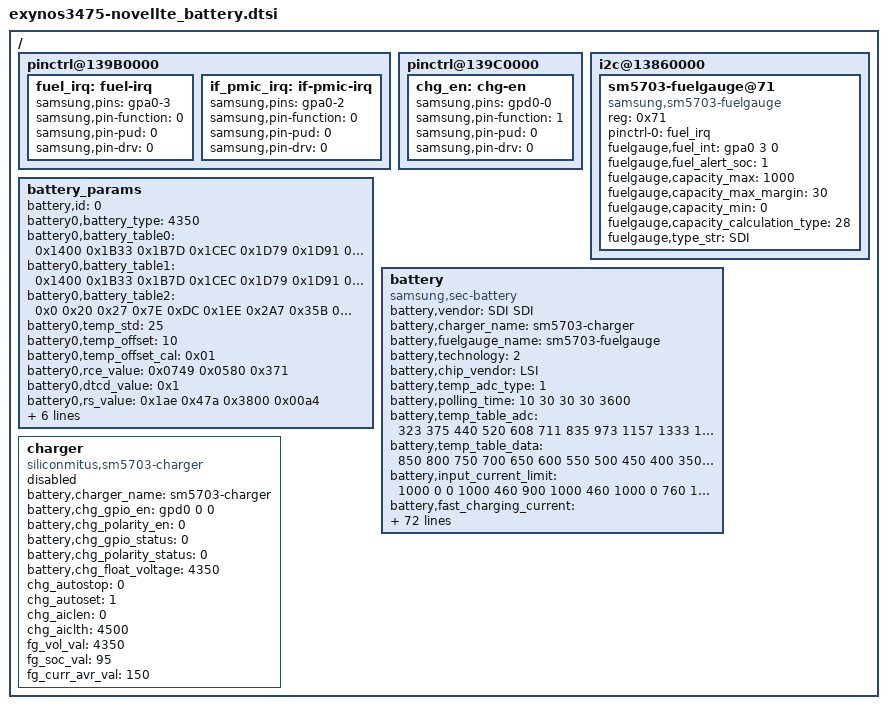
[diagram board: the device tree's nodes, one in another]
/*
 * SAMSUNG UNIVERSAL5430 board device tree source
 *
 * Copyright (c) 2013 Samsung Electronics Co., Ltd.
 *		http://www.samsung.com
 *
 * This program is free software; you can redistribute it and/or modify
 * it under the terms of the GNU General Public License version 2 as
 * published by the Free Software Foundation.
*/

/ {
	pinctrl@139B0000 {
		fuel_irq: fuel-irq {
			samsung,pins = "gpa0-3";
			samsung,pin-function = <0>;
			samsung,pin-pud = <0>;
			samsung,pin-drv = <0>;
		};
	};

	pinctrl@139B0000 {
		if_pmic_irq: if-pmic-irq {
			samsung,pins = "gpa0-2";
			samsung,pin-function = <0>;
			samsung,pin-pud = <0>;
			samsung,pin-drv = <0>;
		};
	};

	pinctrl@139C0000 {
		chg_en: chg-en {
			samsung,pins = "gpd0-0";
			samsung,pin-function = <1>;
			samsung,pin-pud = <0>;
			samsung,pin-drv = <0>;
		};
	};

	i2c@13860000 {
		status = "okay";
		sm5703-fuelgauge@71 {
			compatible = "samsung,sm5703-fuelgauge";
			reg = <0x71>;
			pinctrl-names = "default";
			pinctrl-0 = <&fuel_irq>;
			fuelgauge,fuel_int = <&gpa0 3 0>;
			fuelgauge,fuel_alert_soc = <1>;
			fuelgauge,capacity_max = <1000>;
			fuelgauge,capacity_max_margin = <30>;
			fuelgauge,capacity_min = <0>;
			fuelgauge,capacity_calculation_type = <28>;
			fuelgauge,type_str = "SDI";
		};
	};

	battery_params {
		battery,id = <0>;
		battery0,battery_type = <4350>; /* 4200 4350 4400 */
		battery0,battery_table0 = <0x1400 0x1B33 0x1B7D 0x1CEC 0x1D79 0x1D91 0x1DE9 0x1E19 0x1EA3 0x1EDD 0x1F4E 0x1FD2 0x2086 0x20A5 0x226F 0x2399>;
		battery0,battery_table1 = <0x1400 0x1B33 0x1B7D 0x1CEC 0x1D79 0x1D91 0x1DE9 0x1E19 0x1EA3 0x1EDD 0x1F4E 0x1FD2 0x2086 0x20A5 0x226F 0x2399>;
		battery0,battery_table2 = <0x0 0x20 0x27 0x7E 0xDC 0x1EE 0x2A7 0x35B 0x6F1 0x7A9 0x861 0x9CE 0xAE1 0xB3F 0xE1C 0xE20>;
		battery0,temp_std = <25>;
		battery0,temp_offset = <10>;
		battery0,temp_offset_cal = <0x01>;
		battery0,rce_value = <0x0749 0x0580 0x371>;
		battery0,dtcd_value = <0x1>;
		battery0,rs_value = <0x1ae 0x47a 0x3800 0x00a4>; /*rs mix_factor max min*/
		battery0,vit_period = <0x350a>;
		battery0,mix_value = <0x0503 0x0004>; /*mix_rate init_blank*/
		battery0,topoff_soc = <0x0 0x05>; /*disable soc*/
		battery0,volt_cal = <0x8000>;
		battery0,curr_cal = <0x7900>;
		battery0,charge_offset_cal = <0x01>;
	};

	battery {
		status = "okay";

		pinctrl-names = "default";

		compatible = "samsung,sec-battery";
		battery,vendor = "SDI SDI";
		battery,charger_name = "sm5703-charger";
		battery,fuelgauge_name = "sm5703-fuelgauge";
		battery,technology = <2>; /* POWER_SUPPLY_TECHNOLOGY_LION */
		/* .temp_cohot = -1000; */
		/* .temp_cocold = -4325; */

		battery,chip_vendor = "LSI";
		battery,temp_adc_type = <1>; /* SEC_BATTERY_ADC_TYPE_AP */

		battery,polling_time = <10 30 30 30 3600>;

		battery,temp_table_adc = <323 375 440 520 608 711 835 973 1157 1333 1526 1735 1962 2198
								2430 2661 2876 3111 3290 3447 3581 3695 >;

	        battery,temp_table_data = <850 800 750 700 650 600 550 500 450 400 350 300 250 200
								150 100 50 0 (-50) (-100) (-150) (-200)>;

		battery,input_current_limit = <1000 0 0 1000 460 900 1000 460 1000 0 760 1000 1000 0 0 400 700 1000 300 1000 1600 0 1000 1000 1000 80 1000 1000 1000 450>;
		battery,fast_charging_current = <1000 0 0 1000 460 1000 1000 460 1000 0 900 1000 1000 0 0 400 700 1000 300 1000 1000 0 1000 1000 1000 80 1000 1000 1000 450>;
		battery,full_check_current_1st = <125 0 0 125 125 125 125 125 125 0 125 125 125 0 0 125 125 125 125 125 125 0 125 125 125 0 125 125 125 125>;
		battery,full_check_current_2nd = <2400 0 0 2400 2400 2400 2400 2400 2400 0 2400 2400 2400 0 0 2400 2400 2400 2400 2400 2400 0 2400 2400 2400 2400 2400 2400 2400 2400>;

		battery,adc_check_count = <5>;

		battery,cable_check_type = <4>; /* SEC_BATTERY_CABLE_CHECK_PSY */
		battery,cable_source_type = <1>; /* SEC_BATTERY_CABLE_SOURCE_EXTERNAL */
		battery,event_waiting_time = <600>;
		battery,polling_type = <1>; /* SEC_BATTERY_MONITOR_ALARM */
		battery,monitor_initial_count = <0>;

		battery,battery_check_type = <1>; /* SEC_BATTERY_CHECK_ADC */
		battery,check_count = <0>;
		battery,check_adc_max = <1440>;
		battery,check_adc_min = <0>;

		battery,ovp_uvlo_check_type = <3>; /* SEC_BATTERY_OVP_UVLO_CHGPOLLING */

		battery,thermal_source = <2>; /* SEC_BATTERY_THERMAL_SOURCE_ADC */

		battery,temp_check_type = <2>; /* SEC_BATTERY_TEMP_CHECK_TEMP */
		battery,temp_check_count = <1>;
		battery,temp_highlimit_threshold_event = <800>;
		battery,temp_highlimit_recovery_event = <750>;
		battery,temp_high_threshold_event = <580>;
		battery,temp_high_recovery_event = <530>;
		battery,temp_low_threshold_event = <(-60)>;
		battery,temp_low_recovery_event = <0>;
		battery,temp_highlimit_threshold_normal = <800>;
		battery,temp_highlimit_recovery_normal = <750>;
		battery,temp_high_threshold_normal = <580>;
		battery,temp_high_recovery_normal = <530>;
		battery,temp_low_threshold_normal = <(-60)>;
		battery,temp_low_recovery_normal = <0>;
		battery,temp_highlimit_threshold_lpm = <800>;
		battery,temp_highlimit_recovery_lpm = <750>;
		battery,temp_high_threshold_lpm = <580>;
		battery,temp_high_recovery_lpm = <530>;
		battery,temp_low_threshold_lpm = <(-60)>;
		battery,temp_low_recovery_lpm = <0>;
		
		battery,full_check_type = <7>; /* SEC_BATTERY_FULLCHARGED_CHGPSY */
		battery,full_check_type_2nd = <3>; /* SEC_BATTERY_FULLCHARGED_TIME */
		battery,full_check_count = <1>;
		battery,chg_gpio_full_check = <0>;
		battery,chg_polarity_full_check = <1>;

		/* SEC_BATTERY_FULL_CONDITION_SOC |
		   SEC_BATTERY_FULL_CONDITION_NOTIMEFULL |
		   SEC_BATTERY_FULL_CONDITION_VCELL */
		battery,full_condition_type = <13>;
		battery,full_condition_soc = <93>;
		battery,full_condition_vcell = <4250>;

		battery,recharge_check_count = <1>;
		battery,recharge_condition_type = <4>; /* SEC_BATTERY_RECHARGE_CONDITION_VCELL */
		battery,recharge_condition_soc = <98>;
		battery,recharge_condition_vcell = <4300>;

		battery,charging_total_time = <21600>;
		battery,recharging_total_time = <5400>;
		battery,charging_reset_time = <0>;

		battery,always_enable;

		io-channels = <&exynos_adc 0>, <&exynos_adc 4>;
		io-channel-names = "adc-temp", "bat-check-adc";
		#io-channel-cells = <2>;
		io-channel-ranges;

		battery,chg_float_voltage = <4350>;

		battery,self_discharging_en;
		battery,force_discharging_limit = <650>;
		battery,force_discharging_recov = <550>;
		battery,self_discharging_voltage_limit = <4250>;
		battery,discharging_adc_max = <2600>;
		battery,discharging_adc_min = <1700>;
		battery,discharging_ntc_limit = <2750>;

		battery,swelling_high_temp_block = <500>;
		battery,swelling_high_temp_recov = <450>;
		battery,swelling_low_temp_block = <50>;
		battery,swelling_low_temp_recov = <100>;
		battery,swelling_chg_current = <900>;
		battery,swelling_drop_float_voltage = <4200>;
		battery,swelling_high_rechg_voltage = <4150>;
		battery,swelling_low_rechg_voltage = <4050>;
		battery,swelling_block_time = <600>;
	};

	charger {
		status = "disable";
		compatible = "siliconmitus,sm5703-charger";

		/* Charger */
		battery,charger_name = "sm5703-charger";
		battery,chg_gpio_en = <&gpd0 0 0>;
		battery,chg_polarity_en = <0>;
		battery,chg_gpio_status = <0>;
		battery,chg_polarity_status = <0>;
		battery,chg_float_voltage = <4350>;
		chg_autostop = <0>;
		chg_autoset = <1>;
		chg_aiclen = <0>;
		chg_aiclth = <4500>;
		fg_vol_val = <4350>;
		fg_soc_val = <95>;
		fg_curr_avr_val = <150>;
	};
};
